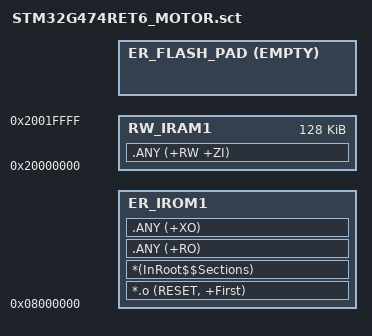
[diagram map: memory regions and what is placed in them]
; Custom scatter — do NOT enable "Use Memory Layout from Target Dialog" in Keil Linker tab.
; App 508 KB (0x7F000); factory_nvm @ 0x0807F000 (4 KB, not linked here).
; ER_FLASH_PAD: 0xFF fill to 2 KB page boundary (after RO + RW load image).

LR_IROM1 0x08000000 0x0007F000  {
  ER_IROM1 0x08000000  {
   *.o (RESET, +First)
   *(InRoot$$Sections)
   .ANY (+RO)
   .ANY (+XO)
  }
  RW_IRAM1 0x20000000 0x00020000  {
   .ANY (+RW +ZI)
  }
  ER_FLASH_PAD +0 FILL 0xFFFFFFFF ALIGN 0x800 EMPTY 0 { }
}
